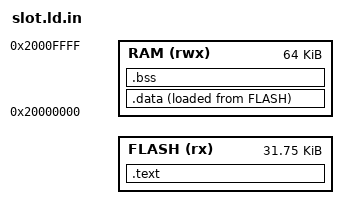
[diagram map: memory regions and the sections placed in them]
/* slot.ld.in - linker script template for an application image in a boot slot (F3-41).
 * run.sh replaces @ORIGIN@ by slot + 0x100 (A: 0x4100, B: 0xC100). */
MEMORY
{
    FLASH (rx)  : ORIGIN = @ORIGIN@, LENGTH = 0x7F00
    RAM   (rwx) : ORIGIN = 0x20000000, LENGTH = 64K
}
ENTRY(Reset_Handler)
SECTIONS
{
    .text : { KEEP(*(.vectors)) *(.text .text.*) *(.rodata .rodata.*) . = ALIGN(4);
              __init_array_start = .; KEEP(*(.init_array .init_array.*)) __init_array_end = .;
              __text_end = .; } > FLASH
    .data : { . = ALIGN(4); __data_start = .; *(.data .data.*) . = ALIGN(4); __data_end = .; } > RAM AT > FLASH
    __data_load = LOADADDR(.data);
    .bss (NOLOAD) : { . = ALIGN(4); __bss_start = .; *(.bss .bss.* COMMON) . = ALIGN(4); __bss_end = .; } > RAM
    __stack_top = ORIGIN(RAM) + LENGTH(RAM);
    /DISCARD/ : { *(.ARM.exidx*) *(.comment) }
}
